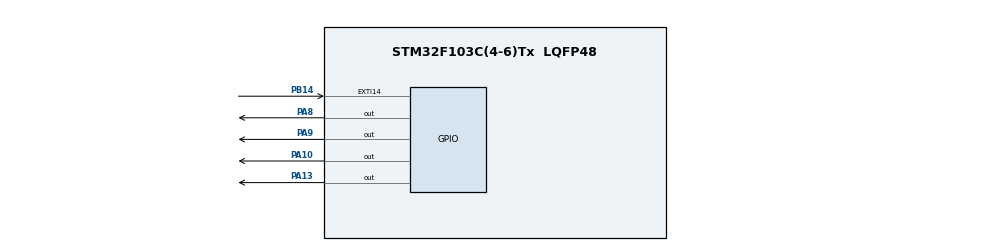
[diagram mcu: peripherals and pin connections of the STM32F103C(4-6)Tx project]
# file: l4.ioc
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Mcu.Family=STM32F1
Mcu.Name=STM32F103C(4-6)Tx
Mcu.Package=LQFP48
NVIC.EXTI15_10_IRQn=true\:0\:0\:false\:true\:true\:2\:true\:true\:true
NVIC.PriorityGroup=NVIC_PRIORITYGROUP_4
NVIC.TIM2_IRQn=true\:0\:0\:false\:true\:true\:1\:true\:true\:true
PA10.Signal=GPIO_Output
PA13.Signal=GPIO_Output
PA8.Signal=GPIO_Output
PA9.Signal=GPIO_Output
PB14.Signal=GPXTI14
ProjectManager.HeapSize=0x200
ProjectManager.StackSize=0x400
ProjectManager.TargetToolchain=STM32CubeIDE
RCC.APB1Freq_Value=8000000
RCC.APB2Freq_Value=8000000
TIM2.Period=200
TIM2.Prescaler=8000
VP_TIM2_VS_ClockSourceINT.Mode=Internal
board=custom

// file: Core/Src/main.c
/* USER CODE BEGIN Header */
/**
  ******************************************************************************
  * @file           : main.c
  * @brief          : Main program body
  ******************************************************************************
  * @attention
  *
  * Copyright (c) 2022 STMicroelectronics.
  * All rights reserved.
  *
  * This software is licensed under terms that can be found in the LICENSE file
  * in the root directory of this software component.
  * If no LICENSE file comes with this software, it is provided AS-IS.
  *
  ******************************************************************************
  */
/* USER CODE END Header */
#include "main.h"
#include "tim.h"
#include "gpio.h"

/* USER CODE BEGIN PV */
int S = 0;
/* USER CODE END PV */

void SystemClock_Config(void);
static void MX_NVIC_Init(void);

int main(void)
{

  /* MCU Configuration--------------------------------------------------------*/

  /* Reset of all peripherals, Initializes the Flash interface and the Systick. */
  HAL_Init();

  /* Configure the system clock */
  SystemClock_Config();

  /* Initialize all configured peripherals */
  MX_GPIO_Init();
  MX_TIM2_Init();

  /* Initialize interrupts */
  MX_NVIC_Init();

  /* Infinite loop */
  while (1)
  {
	  if(HAL_GPIO_ReadPin(GPIOA, GPIO_PIN_14) == GPIO_PIN_RESET)
	 		  S = 0;

	 	  if (S == 0)
	 	    {
	 	    HAL_TIM_Base_Start_IT(&htim2);
	 	    HAL_TIM_Base_Start_IT(&htim2);
	 	    HAL_TIM_Base_Start_IT(&htim2);
	 	    }else
	 	    {
	 	  	  HAL_TIM_Base_Stop_IT(&htim2);
	 	  	  HAL_TIM_Base_Stop_IT(&htim2);
	 	  	  HAL_TIM_Base_Stop_IT(&htim2);
	 	    }

	 	  HAL_GPIO_TogglePin(GPIOA, GPIO_PIN_13);
	 	  HAL_Delay(500);
  }
}

void SystemClock_Config(void)
{
  RCC_OscInitTypeDef RCC_OscInitStruct = {0};
  RCC_ClkInitTypeDef RCC_ClkInitStruct = {0};

  /** Initializes the RCC Oscillators according to the specified parameters
  * in the RCC_OscInitTypeDef structure.
  */
  RCC_OscInitStruct.OscillatorType = RCC_OSCILLATORTYPE_HSI;
  RCC_OscInitStruct.HSIState = RCC_HSI_ON;
  RCC_OscInitStruct.HSICalibrationValue = RCC_HSICALIBRATION_DEFAULT;
  RCC_OscInitStruct.PLL.PLLState = RCC_PLL_NONE;
  if (HAL_RCC_OscConfig(&RCC_OscInitStruct) != HAL_OK)
  {
    Error_Handler();
  }

  /** Initializes the CPU, AHB and APB buses clocks
  */
  RCC_ClkInitStruct.ClockType = RCC_CLOCKTYPE_HCLK|RCC_CLOCKTYPE_SYSCLK
                              |RCC_CLOCKTYPE_PCLK1|RCC_CLOCKTYPE_PCLK2;
  RCC_ClkInitStruct.SYSCLKSource = RCC_SYSCLKSOURCE_HSI;
  RCC_ClkInitStruct.AHBCLKDivider = RCC_SYSCLK_DIV1;
  RCC_ClkInitStruct.APB1CLKDivider = RCC_HCLK_DIV1;
  RCC_ClkInitStruct.APB2CLKDivider = RCC_HCLK_DIV1;

  if (HAL_RCC_ClockConfig(&RCC_ClkInitStruct, FLASH_LATENCY_0) != HAL_OK)
  {
    Error_Handler();
  }
}

/**
  * @brief NVIC Configuration.
  * @retval None
  */
static void MX_NVIC_Init(void)
{
  /* TIM2_IRQn interrupt configuration */
  HAL_NVIC_SetPriority(TIM2_IRQn, 0, 0);
  HAL_NVIC_EnableIRQ(TIM2_IRQn);
  /* EXTI15_10_IRQn interrupt configuration */
  HAL_NVIC_SetPriority(EXTI15_10_IRQn, 0, 0);
  HAL_NVIC_EnableIRQ(EXTI15_10_IRQn);
}

/* USER CODE BEGIN 4 */
void HAL_GPIO_EXTI_Callback(uint16_t GPIO_Pin)
	{
		if (GPIO_Pin == GPIO_PIN_14)
		{
			S = 1;
		}else S = 0;
	}

void HAL_TIM_PeriodElapsedCallback(TIM_HandleTypeDef *htim)
{
	if (htim-> Instance == TIM2)
		{
			HAL_GPIO_TogglePin(GPIOA, GPIO_PIN_8);
		}

	if (htim-> Instance == TIM3)
		{
			HAL_GPIO_TogglePin(GPIOA, GPIO_PIN_9);
		}

	if (htim-> Instance == TIM1)
		{
			HAL_GPIO_TogglePin(GPIOA, GPIO_PIN_10);
		}
	}

/* USER CODE END 4 */

void Error_Handler(void)
{
  __disable_irq();
  while (1)
  {
  }
}
